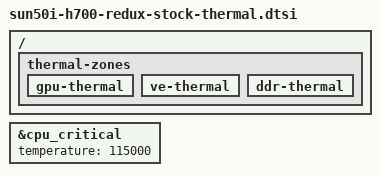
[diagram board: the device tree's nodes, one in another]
// SPDX-License-Identifier: (GPL-2.0-only OR BSD-2-Clause)
/*
 * Decision Q1 (Dale, 2026-11-14), option (a): stock's CPU critical trip (115 C), and no critical
 * trips on GPU/VE/DDR, which stock does not have (Redux hard rule: the critical trip is never
 * changed from stock). Included by sun50i-h700-anbernic-rg34xx-sp-redux.dts. DRAFT, NOT BOOTED.
 * Stock source: reference/stock-202505/board.dts thermal-zones (cpu 60/70 passive, 115 critical).
 */

&cpu_critical {
	temperature = <115000>;
};

/ {
	thermal-zones {
		gpu-thermal {
			/delete-node/ trips;
		};

		ve-thermal {
			/delete-node/ trips;
		};

		ddr-thermal {
			/delete-node/ trips;
		};
	};
};
